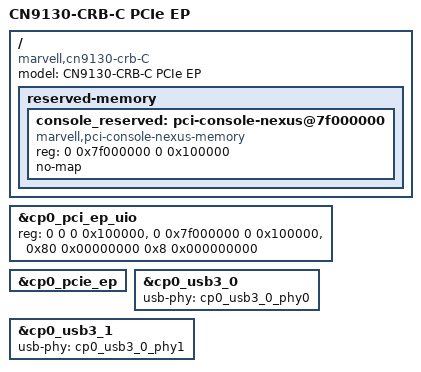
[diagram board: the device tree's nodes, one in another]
// SPDX-License-Identifier: GPL-2.0+
/*
 * Copyright (C) 2019 Marvell International Ltd.
 */

#include "cn9130-crb.dtsi"

/ {
	model = "CN9130-CRB-C PCIe EP";
	compatible = "marvell,cn9130-crb-C",
		"marvell,armada-ap807-quad",
		"marvell,armada-ap807";

	reserved-memory {
		#address-cells = <2>;
		#size-cells = <2>;
		ranges;

		/* The PCI console memory must be reserved */
		console_reserved: pci-console-nexus@7f000000 {
			compatible = "marvell,pci-console-nexus-memory";
			reg = <0 0x7f000000 0 0x100000>;
			no-map;
		};
	};
};

&cp0_pci_ep_uio {
	reg = <0 0 0 0x100000>, <0 0x7f000000 0 0x100000>,
	      <0x80 0x00000000 0x8 0x000000000>;
	reg-names = "bar0", "bar2", "host-map";
	status = "okay";
};

&cp0_pcie_ep {
	status = "okay";
};

&cp0_usb3_0 {
	status = "okay";
	usb-phy = <&cp0_usb3_0_phy0>;
	phy-names = "usb";
};

&cp0_usb3_1 {
	status = "okay";
	usb-phy = <&cp0_usb3_0_phy1>;
	phy-names = "usb";
};
